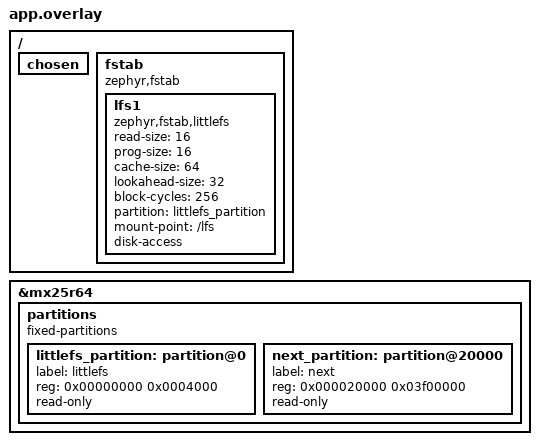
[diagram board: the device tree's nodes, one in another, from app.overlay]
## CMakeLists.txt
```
cmake_minimum_required(VERSION 3.2.0)

set(BOARD   nrf7002dk/nrf5340/cpuapp)
#set(EXTRA_CONF_FILE mcumgr.conf)

find_package(Zephyr REQUIRED HINTS $ENV{ZEPHYR_BASE})

project(nrf7002dk-files-system)


target_sources(app PRIVATE src/main.c)
```

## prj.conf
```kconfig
CONFIG_FLASH=y

CONFIG_LOG=y
#CONFIG_FS_LOG_LEVEL_DBG=y


CONFIG_SHELL=y
CONFIG_SHELL_LOG_LEVEL_INF=y

CONFIG_FILE_SYSTEM=y
CONFIG_FILE_SYSTEM_SHELL=y


CONFIG_FILE_SYSTEM_LITTLEFS=y
CONFIG_FLASH_MAP=y


CONFIG_MPU_ALLOW_FLASH_WRITE=y




CONFIG_FLASH=y

CONFIG_LOG=y

CONFIG_HEAP_MEM_POOL_SIZE=8192

CONFIG_SHELL=y
CONFIG_SHELL_LOG_LEVEL_INF=y

CONFIG_FILE_SYSTEM=y
CONFIG_FILE_SYSTEM_SHELL=y

#CONFIG_SHELL_BACKEND_SERIAL_RX_RING_BUFFER_SIZE=1024

CONFIG_FILE_SYSTEM_LITTLEFS=y
CONFIG_FLASH_MAP=y

CONFIG_FLASH_SHELL=y
CONFIG_FLASH_SHELL_BUFFER_SIZE=2048
CONFIG_NORDIC_QSPI_NOR=y
CONFIG_NORDIC_QSPI_NOR_FLASH_LAYOUT_PAGE_SIZE=4096


CONFIG_FS_LITTLEFS_PROG_SIZE=16
CONFIG_FS_LITTLEFS_READ_SIZE=16
CONFIG_FS_LITTLEFS_PROG_SIZE=16
```

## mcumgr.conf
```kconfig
# Some command handlers require a large stack.
CONFIG_SYSTEM_WORKQUEUE_STACK_SIZE=2304
CONFIG_MAIN_STACK_SIZE=2048

# Enable mcumgr.
CONFIG_MCUMGR=y
CONFIG_MCUMGR_GRP_FS=y

#Enable MCUmgr commands 

CONFIG_MCUMGR_TRANSPORT_SHELL=y
```

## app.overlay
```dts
/ {
    chosen{
        /*zephyr,console = &usb_serial;*/
		/*zephyr,shell-uart = &usb_serial;*/
        /*zephyr,flash-controller = &flash;*/
        
    };


   


    fstab {
		compatible = "zephyr,fstab";
		status="okay";
		lfs1: lfs1 {
			compatible = "zephyr,fstab,littlefs";
			status="okay";
			read-size = <16>;
			prog-size = <16>;
			cache-size = <64>;
			lookahead-size = <32>;
			block-cycles = <256>;
			partition = <&littlefs_partition>;
			mount-point = "/lfs";
            //automount;
            disk-access;
		};
	};

};


&mx25r64 {
	status = "okay";
	partitions {
		compatible = "fixed-partitions";
		#address-cells = <1>;
		#size-cells = <1>;

		littlefs_partition: partition@0 {
			label = "littlefs";
			reg = <0x00000000 0x0004000>; /* 64 MB */
			read-only;
			status = "okay";
		};
		next_partition: partition@20000 {
			label = "next";
			reg = <0x000020000 0x03f00000>; /* 64 MB */
			read-only;
			status = "okay";
		};
	};
};
```

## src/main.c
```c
#include<zephyr/kernel.h>
#include<zephyr/logging/log.h>
#include<zephyr/drivers/gpio.h>

static struct gpio_dt_spec led = GPIO_DT_SPEC_GET(DT_NODELABEL(led1), gpios);

LOG_MODULE_REGISTER(main, LOG_LEVEL_DBG);

int main()

{
    gpio_pin_configure_dt(&led, GPIO_OUTPUT);
    while(1)
    {

     
        k_msleep(1000);
        gpio_pin_toggle_dt(&led);

        //LOG_INF("Hello world");

        
        
    }
}
```
